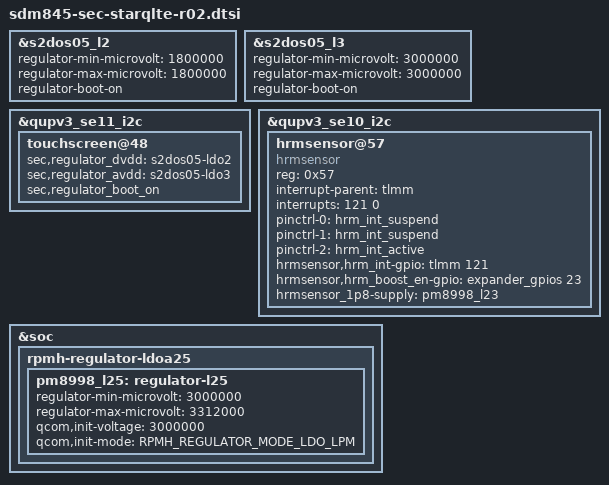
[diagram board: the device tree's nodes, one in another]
/* Copyright (c) 2016-2017, The Linux Foundation. All rights reserved.
 *
 * This program is free software; you can redistribute it and/or modify
 * it under the terms of the GNU General Public License version 2 and
 * only version 2 as published by the Free Software Foundation.
 *
 * This program is distributed in the hope that it will be useful,
 * but WITHOUT ANY WARRANTY; without even the implied warranty of
 * MERCHANTABILITY or FITNESS FOR A PARTICULAR PURPOSE.  See the
 * GNU General Public License for more details.
 */

#include "sdm845-sec-starqlte-r01.dtsi"

&s2dos05_l2 {	/* tsp_io */
	regulator-min-microvolt = <1800000>;
	regulator-max-microvolt = <1800000>;
	regulator-boot-on;
};

&s2dos05_l3 {	/* tsp_avdd */
	regulator-min-microvolt = <3000000>;
	regulator-max-microvolt = <3000000>;
	regulator-boot-on;
};

&qupv3_se11_i2c {
	touchscreen@48 {	/* sec_ts */
		sec,regulator_dvdd = "s2dos05-ldo2";
		sec,regulator_avdd = "s2dos05-ldo3";
		sec,regulator_boot_on;
	};
};

&qupv3_se10_i2c {
	status = "ok";
	hrmsensor@57 {
		compatible = "hrmsensor";
		reg = <0x57>;
		interrupt-parent = <&tlmm>;
		interrupts = <121 0>;
		pinctrl-names = "sleep", "default", "idle";
		pinctrl-0 = <&hrm_int_suspend>;
		pinctrl-1 = <&hrm_int_suspend>;
		pinctrl-2 = <&hrm_int_active>;
		hrmsensor,hrm_int-gpio = <&tlmm 121 0x00>;
		hrmsensor,hrm_boost_en-gpio = <&expander_gpios 23 0>;
		hrmsensor_1p8-supply = <&pm8998_l23>;
	};
};

&soc {
	rpmh-regulator-ldoa25 {
		pm8998_l25: regulator-l25 {
			regulator-min-microvolt = <3000000>;
			regulator-max-microvolt = <3312000>;
			qcom,init-voltage = <3000000>;
			qcom,init-mode = <RPMH_REGULATOR_MODE_LDO_LPM>;
			/delete-property/regulator-always-on;
		};
	};
};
